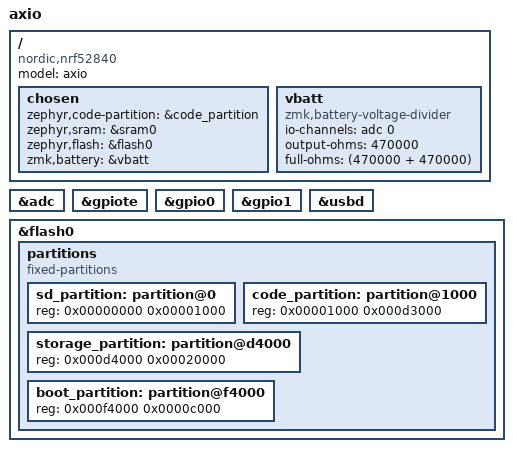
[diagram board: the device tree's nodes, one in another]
/*
 * Copyright (c) 2017 Linaro Limited
 *
 * SPDX-License-Identifier: Apache-2.0
 */

/dts-v1/;


#include <nordic/nrf52840_qiaa.dtsi>
#include <zephyr/dt-bindings/input/input-event-codes.h>
#include <dt-bindings/zmk/matrix_transform.h>

/ {
	model = "axio";
	compatible = "nordic,nrf52840";
    chosen {
        zephyr,code-partition = &code_partition;
        zephyr,sram = &sram0;
        zephyr,flash = &flash0;
        zmk,battery = &vbatt;

    };
/*    
    vbatt: vbatt {
        compatible = "zmk,battery-nrf-vddh";
    };
*/
    
    vbatt: vbatt {
        compatible = "zmk,battery-voltage-divider";
        io-channels = <&adc 0>;
        output-ohms = <470000>;
        full-ohms = <(470000 + 470000)>;
    };


};

&adc {
    status = "okay";
};

&gpiote {
    status = "okay";
};

&gpio0 {
    status = "okay";
};

&gpio1 {
    status = "okay";
};

zephyr_udc0: &usbd {
    status = "okay";
};

&flash0 {
    /*
     * For more information, see:
     * http://docs.zephyrproject.org/latest/devices/dts/flash_partitions.html
     */
    partitions {
        compatible = "fixed-partitions";
        #address-cells = <1>;
        #size-cells = <1>;

        sd_partition: partition@0 {
            reg = <0x00000000 0x00001000>;
        };

        code_partition: partition@1000 {
            reg = <0x00001000 0x000d3000>;
        };

        /*
         * The flash starting at 0x000d4000 and ending at
         * 0x000f3fff is reserved for use by the application.
         */

        /*
         * Storage partition will be used by FCB/LittleFS/NVS
         * if enabled.
         */
        storage_partition: partition@d4000 {
            reg = <0x000d4000 0x00020000>;
        };

        boot_partition: partition@f4000 {
            reg = <0x000f4000 0x0000c000>;
        };
    };
};
